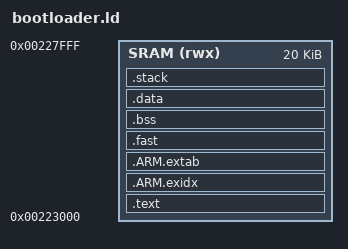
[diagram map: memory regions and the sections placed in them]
/*
 * Copyright 2014, Broadcom Corporation
 * All Rights Reserved.
 *
 * This is UNPUBLISHED PROPRIETARY SOURCE CODE of Broadcom Corporation;
 * the contents of this file may not be disclosed to third parties, copied
 * or duplicated in any form, in whole or in part, without the prior
 * written permission of Broadcom Corporation.
 */

reset_handler = _start;

ENTRY( _start );

/* Include chip specific symbols */
INCLUDE chip_specific_symbols.ld

MEMORY
{
      SRAM (rwx) : ORIGIN = 0x00223000, LENGTH = 20K
}

SECTIONS
{
    .text :
    {
        /* Vector table must be aligned: (from CM3 manual)
         * When setting TBLOFF, you must align the offset to the number of exception
         * entries in the vector table. The minimum alignment is 32 words, enough for
         * up to 16 interrupts. For more interrupts, adjust the alignment by rounding
         * up to the next power of two. For example, if you require 21 interrupts, the
         * alignment must be on a 64-word boundary because the required table size is 37
         * words, and the next power of two is 64. See your vendor documentation for
         * the alignment details for your device.
         */
        . = ALIGN(512);
        link_interrupt_vectors_location = .;
        KEEP(*(*.interrupt_vector_table))


        . = ALIGN(4);
        link_code_location = .;
        KEEP (*(.text._start))
        KEEP (*(.text.irq ))
        *(.text .text.* .gnu.linkonce.t.*)
        link_code_end = .;

        . = ALIGN(0x4);

        link_const_variable_data_location = .;
        *(.rodata .rodata.* .gnu.linkonce.r.*)
        link_const_variable_data_end = .;

        . = ALIGN(0x4);

        link_constructors_location = .;
        KEEP(*(.preinit_array))
        KEEP(*(.init_array))
        KEEP (*crtbegin.o(.ctors))
        KEEP (*(EXCLUDE_FILE (*crtend.o) .ctors))
        KEEP (*(SORT(.ctors.*)))
        KEEP (*crtend.o(.ctors))
        link_constructors_end = .;

        . = ALIGN(0x4);

        link_destructors_location = .;
        KEEP (*crtbegin.o(.dtors))
        KEEP (*(EXCLUDE_FILE (*crtend.o) .dtors))
        KEEP (*(SORT(.dtors.*)))
        KEEP (*crtend.o(.dtors))
        link_destructors_end = .;

        . = ALIGN(16);

    }>SRAM  AT> SRAM

    /*
     * The .ARM.exidx and .ARM.extab sections are used for C++ exception handling.
     * It is located here for completeness. Bare-metal ARM projects
     * typically cannot afford the overhead associated with C++
     * exceptions handling.
     */
    .ARM.exidx :
    {
        __exidx_start = ALIGN(4);
        *(.ARM.exidx* .gnu.linkonce.armexidx.*)
        __exidx_end = .;
    } > SRAM  AT> SRAM

    .ARM.extab :
    {
        __extab_start = ALIGN(4);
        *(.ARM.extab*)
        __extab_end = .;
    } > SRAM  AT> SRAM

    .fast : /* This section contains code that is run from RAM after being loaded from flash - functions can be put in this section with the C attribute: __attribute__ ((section (".fast"))) */
    {
        link_run_from_ram_code_flash_location = LOADADDR( .fast ); /* This is the location in flash of the code */
        link_run_from_ram_code_ram_location = .;
        *(.fast .fast.* .text.fastcode)
        link_run_from_ram_code_ram_end = .;
    }> SRAM AT> SRAM



    .bss : /* Zero initialised memory used for zero initialised variables */
    {
        link_bss_location = ALIGN(., 4);
        *(.bss*)
        *(COMMON)
        link_bss_end = .;
        . = ALIGN(., 4);
    }> SRAM AT>SRAM


    .data : /* Contains the non-zero initialised global variables */
    {
        link_global_data_initial_values = LOADADDR( .data ); /* This is the location in flash of the initial values of global variables */
        link_global_data_start = .;
        *(.data*)
        link_global_data_end = .;
        . = ALIGN(., 4);
    }> SRAM AT> SRAM


    .stack : /* Contains the initial stack */
    {
        link_stack_location = ALIGN(., 4);
        *(.stack)
        . = ALIGN(MAX(link_stack_location + __STACKSIZE__ , .), 4);
        link_stack_end = .;
    }> SRAM AT>SRAM

    /DISCARD/ :
    {
        *(.ARM.attributes*)
        *(.comment)
        *(.init)
        *(.preinit)
        *(.fini)
        *(.fini_array)
        *(.ARM.exidx*)
        *(.gnu.linkonce.armexidx.*)
        *(.eh_frame_hdr)
        *(.eh_frame)
        *(.gnu.linkonce.armextab.*)
        *(.v4_bx)
        *(.vfp11_veneer)
        *(.gcc_except_table)
        *(.eh_frame_hdr)
        *(.eh_frame)
        *(.glue*)
    }
}



/* Declare libc Heap to start at end of allocated RAM */

PROVIDE( _heap = link_stack_end );

/* End of the heap is top of RAM, aligned 8 byte */

PROVIDE( _eheap = ALIGN( ORIGIN( SRAM ) + LENGTH( SRAM ) - 8, 8 ) );
